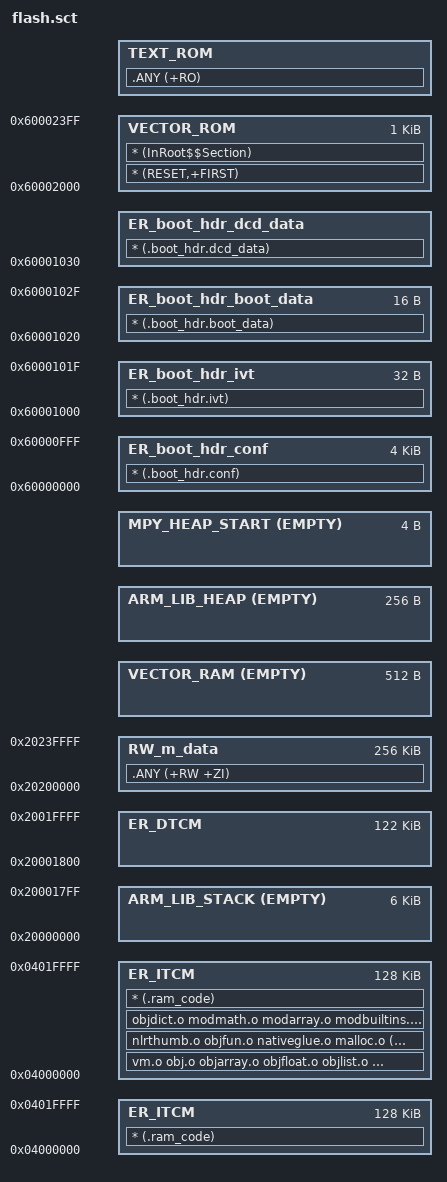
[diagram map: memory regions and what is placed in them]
#! armcc -E

#define STACK_SIZE 0x1800
; must use "VECTOR_RAM", "RW_m_data", "VECTOR_ROM" as names to work with "InstallIRQHandler()" API

LR_XIP_FLASH_INFO 0x60000000  {
  ; >>> RO regions
	ER_boot_hdr_conf +0 0x1000 {
	* (.boot_hdr.conf)
	}
	ER_boot_hdr_ivt 0x60001000 0x20 {
	* (.boot_hdr.ivt)
	}
	ER_boot_hdr_boot_data 0x60001020 0x10{
	* (.boot_hdr.boot_data)
	}  
	ER_boot_hdr_dcd_data 0x60001030{
	* (.boot_hdr.dcd_data)
	}
}

LR_XIP_FLASH 0x60002000 {
	VECTOR_ROM +0 0x400 { ; vector table
		* (RESET,+FIRST)
		* (InRoot$$Section)
	}
	
	TEXT_ROM +0  { ; load address = execution address
		.ANY (+RO)
	}

	ER_ITCM 0x04000000 128*1024 { ; Stack region growing down
		* (.ram_code)
	}

	ER_ITCM 0x04000000 128*1024 { ; Stack region growing down
		vm.o obj.o objarray.o objfloat.o objlist.o objobject.o  (+RO)
		nlrthumb.o objfun.o  nativeglue.o malloc.o (+RO)	
		objdict.o  modmath.o modarray.o modbuiltins.o modmicropython.o map.o (+RO)
		* (.ram_code)
	}
	
	ARM_LIB_STACK 0x20000000 EMPTY STACK_SIZE {}
	ER_DTCM 0x20000000 + STACK_SIZE 128*1024-STACK_SIZE {
	}

	RW_m_data 0x20200000 256*1024 { ; RW data
		.ANY (+RW +ZI)
	
	}
	VECTOR_RAM +0 EMPTY 0x200 { ; RAM vector region (in RAMX)
	} 
	ARM_LIB_HEAP +0 EMPTY 0x100 ; Heap region growing up
	{}
	MPY_HEAP_START +0 EMPTY 4 {
	}
	; <<<

	; >>> SDRAM >>>
	;RW_FB 0xA0000000 EMPTY UNINIT 1024*1024  {
	;}

	;RW_SDRAM 0xA0100000 EMPTY UNINIT (32-1)*1024*1024  {
	;}
	; <<<
}
